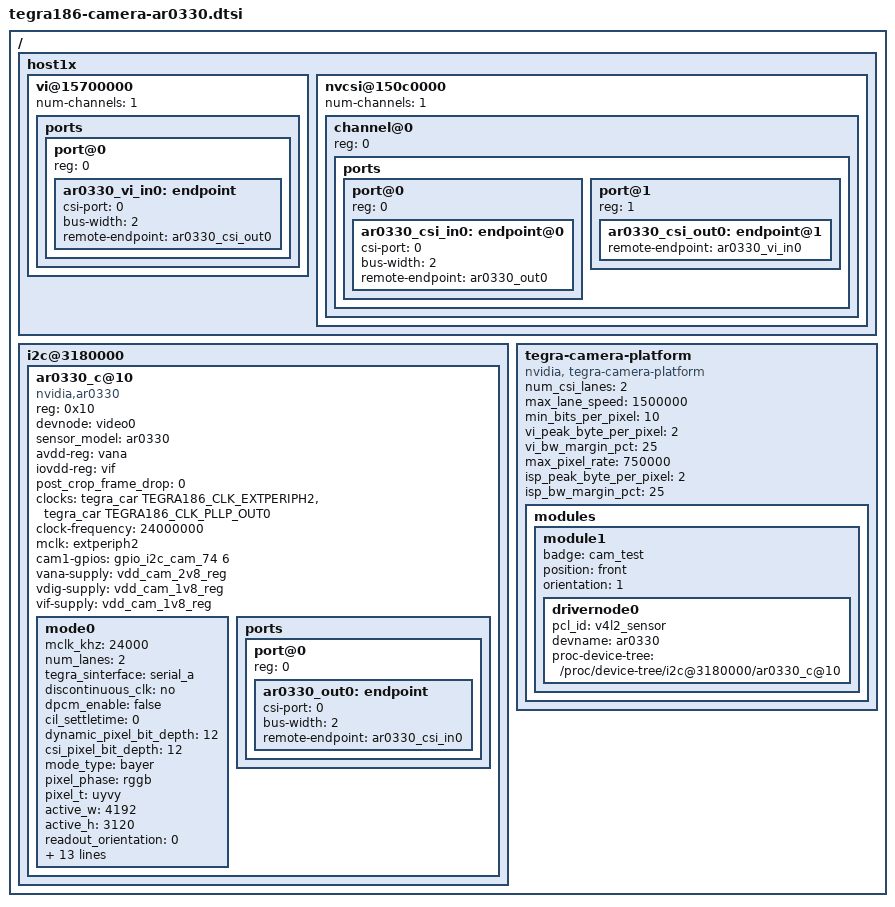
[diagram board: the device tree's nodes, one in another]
/* Device tree for AR0330 camera support
*
* This configures all drivers for the Nobi camera bord connected to the Jetson
* TX2 dev-kit with the interposer board.
*
* TODO: make this entry platform agnostic by moving settings in platform entry.
*
* Based on:
* - https://devtalk.nvidia.com/default/topic/1048530/jetson-tx2/two-csi-cameras-each-work-individually-but-not-at-the-same-time/
* - the imx274 device tree entry.
* - the original DTS for the Tegra TK1: https://github.com/madisongh/linux-tegra/blob/ef19d27ca4d97fe8b4f81dc994e3e4d633b13d0c/arch/arm/boot/dts/tegra124-platforms/tegra124-pm359-camera-a00.dtsi#L181
*/

#include <dt-bindings/media/camera.h>
#include "dt-bindings/clock/tegra186-clock.h"

/* AR0330 ar0330_csi_in0, ar0330_csi_out0 -> ar0330_vi_in0, csi_out0 NVCSI cam_vi_in0 -> cam_vi_in0 VI DMA */

/ {
	host1x { /* The Tegra host1x module is the DMA engine for register access to Tegra’s graphics- and multimedia-related modules. */
		vi@15700000 { /* The Video Input unit. See Parker TRM chapter 27 (page 2773) */
			num-channels= <1>;
			ports {
				#address-cells = <1>;
				#size-cells = <0>;
				port@0 {
					reg = <0>;
					ar0330_vi_in0: endpoint {
						csi-port = <0>;
						bus-width = <2>;
						remote-endpoint = <&ar0330_csi_out0>;
					};
				};
			};
		};

		nvcsi@150c0000 { /* The Parker CSI-2 host solution. See Parker TRM page 31, 2846 and arvi2.h. */
			num-channels = <1>;
			channel@0 {
				reg = <0>;
				ports {
					#address-cells = <1>;
					#size-cells = <0>;
					port@0 {
						reg = <0>;
						ar0330_csi_in0: endpoint@0 {
							csi-port = <0>;
							bus-width = <2>;
							remote-endpoint = <&ar0330_out0>;
						};
					};
					port@1 {
						reg = <1>;
						ar0330_csi_out0: endpoint@1 {
							remote-endpoint = <&ar0330_vi_in0>;
						};
					};
				};
			};
		};

	};

	/* CSI-A is i2c-cam - 3180000 */
	/* TODO: add second address on I2C_CAM and second I2C bus  (c2500000?)*/

	i2c@3180000 {
		status = "okay";
		#address-cells = <1>;
		#size-cells = <0>;
		ar0330_c@10 {
			status = "okay";
			compatible = "nvidia,ar0330";
			reg = <0x10>;
			devnode = "video0";
			sensor_model ="ar0330";
			avdd-reg = "vana";
			iovdd-reg = "vif";

			post_crop_frame_drop = "0";
			/*
			clocks = <&tegra_car TEGRA186_CLK_EXTPERIPH1>,
					 <&tegra_car TEGRA186_CLK_PLLP_OUT0>;
			clock-names = "extperiph1", "pllp_grtba";
			mclk = "extperiph1";
			*/
			clocks = <&tegra_car TEGRA186_CLK_EXTPERIPH2>,
					 <&tegra_car TEGRA186_CLK_PLLP_OUT0>;
			clock-names = "extperiph2", "pllp_grtba";
			clock-frequency = <24000000>;
			mclk = "extperiph2";

			/* Reset pin. Seems to be named cam1-gpios in driver */
			cam1-gpios = <&gpio_i2c_cam_74 6 0>;

			vana-supply = <&vdd_cam_2v8_reg>; /* analog supply */
			vdig-supply = <&vdd_cam_1v8_reg>; /* digital supply */
			vif-supply = <&vdd_cam_1v8_reg>; /* digital IO */

			/**
			* A modeX node is required to support v4l2 driver
			* implementation with NVIDIA camera software stack
			*
			* mclk_khz = "";
			* Standard MIPI driving clock, typically 24MHz
			*
			* num_lanes = "";
			* Number of lane channels sensor is programmed to output
			*
			* tegra_sinterface = "";
			* The base tegra serial interface lanes are connected to
			*
			* discontinuous_clk = "";
			* The sensor is programmed to use a discontinuous clock on MIPI lanes
			*
			* dpcm_enable = "true";
			* The sensor is programmed to use a DPCM modes
			*
			* cil_settletime = "";
			* MIPI lane settle time value.
			* A "0" value attempts to autocalibrate based on mclk_multiplier
			*
			*
			*
			*
			* active_w = "";
			* Pixel active region width
			*
			* active_h = "";
			* Pixel active region height
			*
			* pixel_t = "";
			* The sensor readout pixel pattern
			*
			* readout_orientation = "0";
			* Based on camera module orientation.
			* Only change readout_orientation if you specifically
			* Program a different readout order for this mode
			*
			* line_length = "";
			* Pixel line length (width) for sensor mode.
			* This is used to calibrate features in our camera stack.
			*
			* mclk_multiplier = "";
			* Multiplier to MCLK to help time hardware capture sequence
			* TODO: Assign to PLL_Multiplier as well until fixed in core
			*
			* pix_clk_hz = "";
			* Sensor pixel clock used for calculations like exposure and framerate
			*
			*
			*
			*
			* inherent_gain = "";
			* Gain obtained inherently from mode (ie. pixel binning)
			*
			* min_gain_val = ""; (floor to 6 decimal places)
			* max_gain_val = ""; (floor to 6 decimal places)
			* Gain limits for mode
			*
			* min_exp_time = ""; (ceil to integer)
			* max_exp_time = ""; (ceil to integer)
			* Exposure Time limits for mode (us)
			*
			*
			* min_hdr_ratio = "";
			* max_hdr_ratio = "";
			* HDR Ratio limits for mode
			*
			* min_framerate = "";
			* max_framerate = "";
			* Framerate limits for mode (fps)
			*/
			mode0 { /* mode AR0330 */
				mclk_khz = "24000";
				num_lanes = "2";
				tegra_sinterface = "serial_a";	/* CSI lane A */
				discontinuous_clk = "no";
				dpcm_enable = "false";
				cil_settletime = "0";
				dynamic_pixel_bit_depth = "12";
				csi_pixel_bit_depth = "12";
				mode_type = "bayer";
				pixel_phase = "rggb";
				pixel_t = "uyvy";

				active_w = "4192";
				active_h = "3120";
				readout_orientation = "0";
				line_length = "2200";
				inherent_gain = "1";
				mclk_multiplier = "2";
				pix_clk_hz = "74250000";

				min_gain_val = "0"; /* dB */
				max_gain_val = "48"; /* dB */
				min_hdr_ratio = "1";
				max_hdr_ratio = "1";
				min_framerate = "1.5";
				max_framerate = "30";
				min_exp_time = "30";
				max_exp_time = "660000";
				embedded_metadata_height = "1";
			};
			ports {
				#address-cells = <1>;
				#size-cells = <0>;

				port@0 {
					reg = <0>;
					ar0330_out0: endpoint {
						csi-port = <0>; /* CSI port A */
						bus-width = <2>;
						remote-endpoint = <&ar0330_csi_in0>;
					};
				};
			};
		};
	};

	tegra-camera-platform {
		compatible = "nvidia, tegra-camera-platform";

		num_csi_lanes = <2>;

		/* TODO: double check these values */
		max_lane_speed = <1500000>;
		min_bits_per_pixel = <10>;
		vi_peak_byte_per_pixel = <2>;
		vi_bw_margin_pct = <25>;
		max_pixel_rate = <750000>;
		isp_peak_byte_per_pixel = <2>;
		isp_bw_margin_pct = <25>;

		modules {
			module1 {
				badge = "cam_test";
				position = "front";
				orientation = "1";
				drivernode0 {
					pcl_id = "v4l2_sensor";
					devname = "ar0330 ";
					proc-device-tree = "/proc/device-tree/i2c@3180000/ar0330_c@10";
					status = "okay";
				};
			};
		};
	};
};
